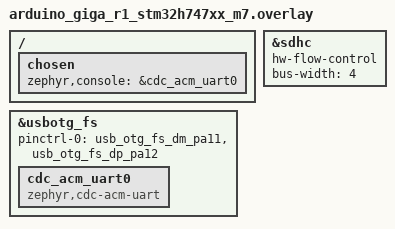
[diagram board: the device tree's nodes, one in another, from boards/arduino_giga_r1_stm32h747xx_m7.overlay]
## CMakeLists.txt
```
# SPDX-License-Identifier: Apache-2.0

cmake_minimum_required(VERSION 3.20.0)
find_package(Zephyr REQUIRED HINTS $ENV{ZEPHYR_BASE})
project(sdhc_read_write)

set(app_sources src/main.c)
target_sources(app PRIVATE ${app_sources})
```

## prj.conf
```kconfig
CONFIG_LOG=y
CONFIG_LOG_DEFAULT_LEVEL=3
CONFIG_LOG_MODE_MINIMAL=y
CONFIG_NETWORKING=y
CONFIG_SDIO_STACK=y
CONFIG_WIFI=y
CONFIG_SDHC_INIT_PRIORITY=75
CONFIG_MAIN_STACK_SIZE=20480
CONFIG_HEAP_MEM_POOL_SIZE=24576
```

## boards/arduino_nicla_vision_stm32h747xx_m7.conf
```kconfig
CONFIG_SDMMC_STM32=y
CONFIG_CYW4343W=y
CONFIG_CYW4343W_MURATA_1DX=y
CONFIG_LOG_MODE_DEFERRED=y
```

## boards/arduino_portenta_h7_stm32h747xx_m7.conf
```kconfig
# Copyright (c) 2022 Benjamin Björnsson <benjamin.bjornsson@gmail.com>.
# SPDX-License-Identifier: Apache-2.0

CONFIG_SDMMC_STM32=y
CONFIG_CYW4343W=y
CONFIG_CYW4343W_MURATA_1DX=y
```

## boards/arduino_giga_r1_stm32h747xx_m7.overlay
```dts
/*
 * Copyright (c) 2025 EXALT Technologies.
 *
 * SPDX-License-Identifier: Apache-2.0
 */

/ {
	chosen {
		zephyr,console = &cdc_acm_uart0;
	};
};

&usbotg_fs {
	status = "okay";
	pinctrl-0 = <&usb_otg_fs_dm_pa11 &usb_otg_fs_dp_pa12>;
	pinctrl-names = "default";

	cdc_acm_uart0: cdc_acm_uart0 {
		status = "okay";
		compatible = "zephyr,cdc-acm-uart";
	};
};

&cdc_acm_uart0 {
	status = "okay";
};

&sdhc {
	hw-flow-control;
	bus-width = <4>;
};
```

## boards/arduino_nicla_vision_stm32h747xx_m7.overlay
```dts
/*
 * Copyright (c) 2025 EXALT Technologies.
 *
 * SPDX-License-Identifier: Apache-2.0
 */

/ {
	chosen {
		zephyr,console = &board_cdc_acm_uart;
	};
};

&zephyr_udc0 {
	clocks = <&rcc STM32_CLOCK_BUS_AHB1 0x6000000>,
		 <&rcc STM32_SRC_HSI48 USB_SEL(3)>;
	num-bidir-endpoints = < 4 >;

	board_cdc_acm_uart: board_cdc_acm_uart {
		status = "okay";
		compatible = "zephyr,cdc-acm-uart";
	};
};

&sdhc {
	hw-flow-control;
	bus-width = <4>;
	clk-div = <8>;
};
```

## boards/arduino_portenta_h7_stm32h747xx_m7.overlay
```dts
/*
 * Copyright (c) 2025 EXALT Technologies.
 *
 * SPDX-License-Identifier: Apache-2.0
 */

&boot_partition{
	reg = <0x00000000 0x00020000>;
};
&scratch_partition {
	reg = <0x00020000 0x00020000>;
};
&slot0_partition {
	reg = <0x00040000 0x001C0000>;
};
&slot1_partition {
	reg = <0x00200000  0x001C0000>;
};
```

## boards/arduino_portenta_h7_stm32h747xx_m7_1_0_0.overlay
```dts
sdhc: &sdmmc1 {
	compatible = "st,stm32-sdhc";
	hw-flow-control;
	bus-width=<4>;
	pinctrl-0 = <&sdmmc1_d0_pc8 &sdmmc1_d1_pc9
			&sdmmc1_d2_pc10 &sdmmc1_d3_pc11
			&sdmmc1_ck_pc12 &sdmmc1_cmd_pd2>;
	pinctrl-names = "default";
	min-bus-freq = <25000000>;
	max-bus-freq = <208000000>;
	sdhi-on-gpios = <&gpioj 1 GPIO_ACTIVE_HIGH>;
	status= "okay";
};
```

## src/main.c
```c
/*
 * Copyright (c) 2025 EXALT Technologies.
 *
 * SPDX-License-Identifier: Apache-2.0
 */

#include <string.h>
#include <stdio.h>
#include <assert.h>
#include <zephyr/kernel.h>
#include <zephyr/device.h>
#include <zephyr/sd/sdio.h>
#include <zephyr/sys/util.h>
#include <zephyr/logging/log.h>
#include <zephyr/drivers/sdhc.h>

LOG_MODULE_REGISTER(sdio_sample, LOG_LEVEL_INF);

static int cmd52_read(const struct device *dev, struct sdhc_command *cmd, enum sdio_func_num func,
						uint32_t reg_addr)
{
	cmd->opcode = SDIO_RW_DIRECT;
	cmd->arg = func << SDIO_CMD_ARG_FUNC_NUM_SHIFT |
		(reg_addr & SDIO_CMD_ARG_REG_ADDR_MASK) << SDIO_CMD_ARG_REG_ADDR_SHIFT;
	cmd->response_type = SD_RSP_TYPE_R5;
	cmd->timeout_ms = CONFIG_SD_CMD_TIMEOUT;
	return sdhc_request(dev, cmd, NULL);
}

static int cmd52_write(const struct device *dev, struct sdhc_command *cmd, enum sdio_func_num func,
						uint32_t reg_addr, uint8_t data_in)
{
	cmd->opcode = SDIO_RW_DIRECT;
	cmd->arg = func << SDIO_CMD_ARG_FUNC_NUM_SHIFT |
		(reg_addr & SDIO_CMD_ARG_REG_ADDR_MASK) << SDIO_CMD_ARG_REG_ADDR_SHIFT;
	cmd->arg |= data_in;
	cmd->arg |= BIT(SDIO_CMD_ARG_RW_SHIFT);
	if (data_in) {
		cmd->arg |= BIT(SDIO_DIRECT_CMD_ARG_RAW_SHIFT);
	}
	cmd->response_type = SD_RSP_TYPE_R5;
	cmd->timeout_ms = CONFIG_SD_CMD_TIMEOUT;
	return sdhc_request(dev, cmd, NULL);
}

int main(void)
{
	int res;
	uint8_t data;
	uint8_t read_data;
	struct sdhc_command cmd = {0};
	enum sdio_func_num func_num = SDIO_FUNC_NUM_0;

	const struct device *sdmmc_dev = DEVICE_DT_GET(DT_NODELABEL(sdhc));

	if (!device_is_ready(sdmmc_dev)) {
		LOG_ERR("SDHC %s is not ready", sdmmc_dev->name);
		return -1;
	}

	res = cmd52_read(sdmmc_dev, &cmd, func_num, SDIO_CCCR_INT_EN);
	if (res == 0) {
		data = cmd.response[0U];
		LOG_INF("CMD52 READ passed: data = 0x%02X", cmd.response[0U]);
	} else {
		LOG_ERR("CMD52 READ failed");
		return -1;
	}

	data = data | BIT(SDIO_FUNC_NUM_1);
	/* Enabling function 1 interrupt by writing to SDIO_CCCR_INT_EN */
	res = cmd52_write(sdmmc_dev, &cmd, func_num, SDIO_CCCR_INT_EN, data);
	if (res == 0) {
		LOG_INF("CMD52 WRITE passed: wrote 0x%02X", data);
	} else {
		LOG_ERR("CMD52 WRITE failed for data 0x%02X", data);
		return -1;
	}

	res = cmd52_read(sdmmc_dev, &cmd, func_num, SDIO_CCCR_INT_EN);
	if (res == 0) {
		read_data = cmd.response[0U];
		if (read_data == data) {
			LOG_INF("read data after write was as expected, data = 0x%02X", read_data);
		} else {
			LOG_ERR("read data was not as expected, expected 0x%02X, got 0x%02X",
				data, read_data);
			return -1;
		}
	} else {
		LOG_ERR("CMD52 READ (post-write) failed");
		return -1;
	}

	return 0;
}
```
